# ARMv6-M-SYST register map
Registers from a debugger description file.
Registers are 32-bit, access not given, no defined reset value unless marked. A register's access mark holds for its fields unless they carry their own. Addresses are absolute; registers are grouped by the start of their names; lines under a group give offsets from that group; [hi:lo] are bit positions; {n}, {i} and the like mark numbered series; 'fields as' and 'values as' point back to an identical list; <NAME> marks a mode.

## SFR
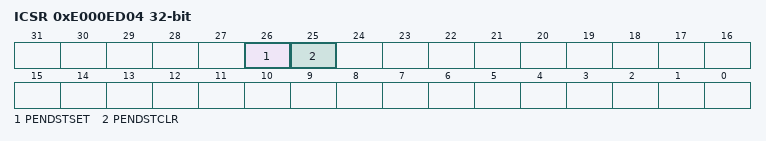
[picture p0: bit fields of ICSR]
0xE000ED04 ICSR
  [26] PENDSTSET, [25] PENDSTCLR
0xE000ED20 SHPR3
  [31:30] PRI_15

## SYST
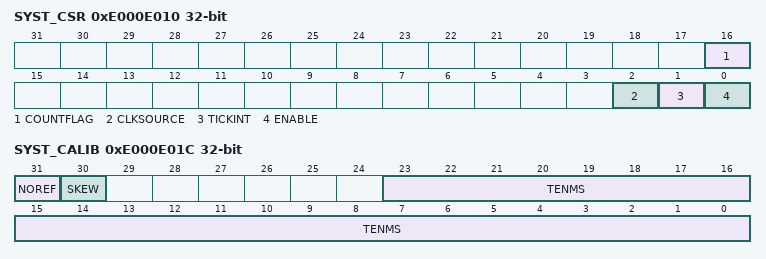
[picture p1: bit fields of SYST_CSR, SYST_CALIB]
0xE000E010 SYST_CSR — SysTick Control and Status Register
  [16] COUNTFLAG, [2] CLKSOURCE, [1] TICKINT, [0] ENABLE
0xE000E014 SYST_RVR — SysTick Reload Value Register
  [23:0] RELOAD
0xE000E018 SYST_CVR — SysTick Current Value Register
  [23:0] CURRENT
0xE000E01C SYST_CALIB ro — SysTick Calibration Value Register
  [31] NOREF, [30] SKEW, [23:0] TENMS
